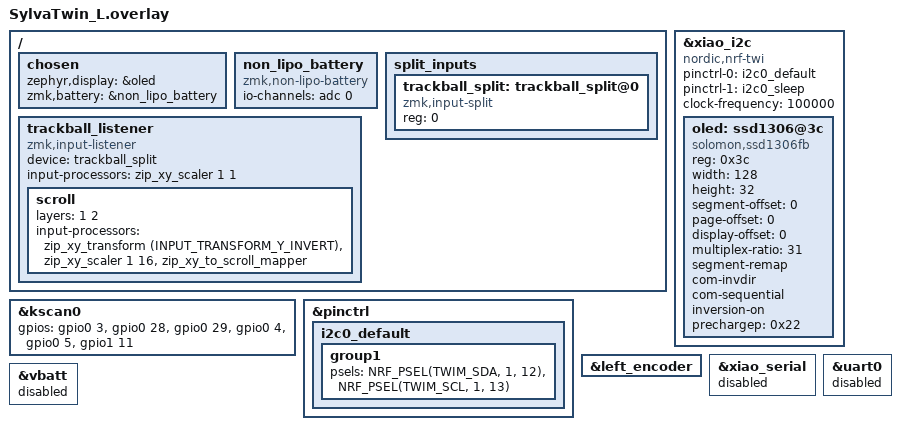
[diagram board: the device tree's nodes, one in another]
/*
 * Copyright (c) 2020 Pete Johanson
 *
 * SPDX-License-Identifier: MIT
 */

#include <dt-bindings/zmk/bt.h>
#include <input/processors.dtsi>
#include <dt-bindings/zmk/input_transform.h>
#include <zephyr/dt-bindings/input/input-event-codes.h>
#include <dt-bindings/zmk/keys.h>
#include <dt-bindings/zmk/pointing.h>
#include "SylvaTwin.dtsi"

/ {
    chosen {
        zephyr,display = &oled;
        zmk,battery = &non_lipo_battery;
    };
    
    non_lipo_battery: non_lipo_battery {
        compatible = "zmk,non-lipo-battery";
        io-channels = <&adc 0>;  // 使用するADCチャンネル
    };
    
    split_inputs {
        #address-cells = <1>;
        #size-cells = <0>;

        trackball_split: trackball_split@0 {
            compatible = "zmk,input-split";
            reg = <0>;
        };
    };

    trackball_listener: trackball_listener {
        compatible = "zmk,input-listener";
        status = "okay";
        device = <&trackball_split>;
        
        input-processors =
            <&zip_xy_scaler 1 1>;
                
        scroll {
            layers = <1 2>;
            input-processors = <&zip_xy_transform (INPUT_TRANSFORM_Y_INVERT)>,
                               <&zip_xy_scaler 1 16>,
                               <&zip_xy_to_scroll_mapper>;
        };
    };
};

&kscan0 {
        gpios
          = <&gpio0  3 GPIO_ACTIVE_HIGH>
          , <&gpio0 28 GPIO_ACTIVE_HIGH>
          , <&gpio0 29 GPIO_ACTIVE_HIGH>
          , <&gpio0  4 GPIO_ACTIVE_HIGH>
          , <&gpio0  5 GPIO_ACTIVE_HIGH>
          , <&gpio1 11 GPIO_ACTIVE_HIGH>
          ;
};

&pinctrl {
    i2c0_default: i2c0_default {
        group1 {
            psels = <NRF_PSEL(TWIM_SDA, 1, 12)>,
                    <NRF_PSEL(TWIM_SCL, 1, 13)>;
        };
    };
};

&xiao_i2c {
    status = "okay";
    compatible = "nordic,nrf-twi";
    pinctrl-0 = <&i2c0_default>;
    pinctrl-1 = <&i2c0_sleep>;
    pinctrl-names = "default", "sleep";
    
    clock-frequency = <100000>; 
    oled: ssd1306@3c {
        compatible = "solomon,ssd1306fb";
        reg = <0x3c>;
        width = <128>;
        height = <32>;
        segment-offset = <0>;
        page-offset = <0>;
        display-offset = <0>;
        multiplex-ratio = <31>;
        segment-remap;
        com-invdir;
        com-sequential;
        inversion-on;
        prechargep = <0x22>;
    };
};

&left_encoder {
    status = "okay";
};

&xiao_serial { status = "disabled"; };
&uart0 { status = "disabled";};
&vbatt { status = "disabled";};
